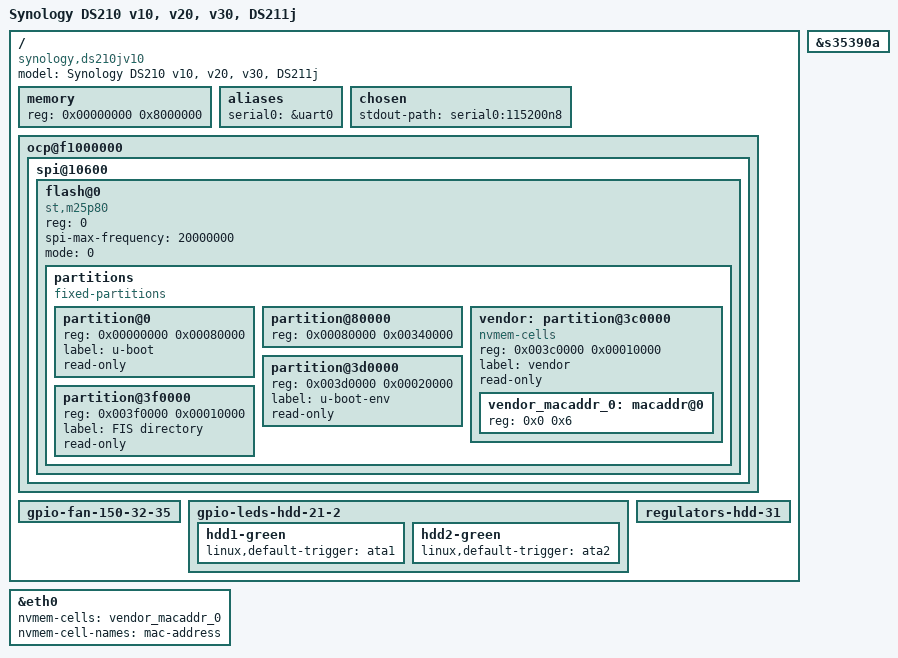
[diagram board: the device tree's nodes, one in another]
// SPDX-License-Identifier: GPL-2.0
/*
 * Andrew Lunn <andrew@lunn.ch>
 * Ben Peddell <klightspeed@killerwolves.net>
 *
 */

/dts-v1/;

#include "kirkwood.dtsi"
#include "kirkwood-6281.dtsi"
#include "kirkwood-synology.dtsi"

/ {
	model = "Synology DS210 v10, v20, v30, DS211j";
	compatible = "synology,ds210jv10", "synology,ds210jv20",
		     "synology,ds210jv30", "synology,ds211j",
		     "marvell,kirkwood";

	memory {
		device_type = "memory";
		reg = <0x00000000 0x8000000>;
	};

	aliases {
		serial0 = &uart0;
	};

	chosen {
		//bootargs = "console=ttyS0,115200n8";
		stdout-path = "serial0:115200n8";
	};

	ocp@f1000000 {
		spi@10600 {
			status = "okay";

			flash@0 {
				#address-cells = <1>;
				#size-cells = <1>;
				compatible = "st,m25p80", "jedec,spi-nor";
				reg = <0>;
				spi-max-frequency = <20000000>;
				mode = <0>;

				partitions {
					compatible = "fixed-partitions";
					#address-cells = <1>;
					#size-cells = <1>;

					partition@0 {
						reg = <0x00000000 0x00080000>;
						label = "u-boot";
						read-only;
					};

					/* This combines stock kernel and rd.gz partitions */
					/* TODO Store FDT here? */
					partition@80000 {
						//compatible = "denx,uImage";
						reg = <0x00080000 0x00340000>;
						//label = "kernel";
					};

					vendor: partition@3c0000 {
						reg = <0x003c0000 0x00010000>;
						label = "vendor";
						read-only;
						compatible = "nvmem-cells";
						#address-cells = <1>;
						#size-cells = <1>;

						vendor_macaddr_0: macaddr@0 {
							reg = <0x0 0x6>;
						};

						/* TODO device serial */
					};

					partition@3d0000 {
						reg = <0x003d0000 0x00020000>;
						label = "u-boot-env";
						read-only;
					};

					partition@3f0000 {
						reg = <0x003f0000 0x00010000>;
						label = "FIS directory";
						read-only;
					};
				};
			};
		};
	};

	gpio-fan-150-32-35 {
		status = "okay";
	};

	gpio-leds-hdd-21-2 {
		status = "okay";

		hdd1-green {
			linux,default-trigger = "ata1";
		};

		hdd2-green {
			linux,default-trigger = "ata2";
		};
	};

	regulators-hdd-31 {
		status = "okay";
	};
};

&s35390a {
	status = "okay";
};

&eth0 {
	nvmem-cells = <&vendor_macaddr_0>;
	nvmem-cell-names = "mac-address";
};
